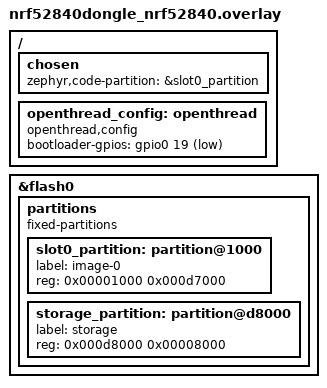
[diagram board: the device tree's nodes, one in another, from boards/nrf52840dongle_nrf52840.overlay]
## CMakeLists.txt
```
#
# Matter temperature sensor on the nRF52840 Dongle.
#
# Based on nrf/samples/matter/temperature_sensor (Nordic-5-Clause).
#

cmake_minimum_required(VERSION 3.20.0)

find_package(Zephyr HINTS $ENV{ZEPHYR_BASE})

project(ansim-sensor-dongle)

# Enable GNU STD support.
include(${ZEPHYR_CONNECTEDHOMEIP_MODULE_DIR}/config/nrfconnect/app/enable-gnu-std.cmake)

# Include all source files that are located in the Matter common directory.
include(${ZEPHYR_NRF_MODULE_DIR}/samples/matter/common/cmake/source_common.cmake)

# Include Data Model utils
include(${ZEPHYR_NRF_MODULE_DIR}/samples/matter/common/cmake/data_model.cmake)

include(${ZEPHYR_NRF_MODULE_DIR}/samples/matter/common/cmake/zap_helpers.cmake)
ncs_get_zap_parent_dir(ZAP_PARENT_DIR)

target_include_directories(app PRIVATE
  src
  ${CMAKE_CURRENT_SOURCE_DIR}/../common
  ${ZAP_PARENT_DIR}
)

target_sources(app PRIVATE
  src/app_task.cpp
  src/main.cpp
  ${CMAKE_CURRENT_SOURCE_DIR}/../common/status_log.cpp
)

ncs_configure_data_model()
```

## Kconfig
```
#
# Matter temperature sensor on the nRF52840 Dongle.
#
# Based on nrf/samples/matter/temperature_sensor (Nordic-5-Clause).
#
mainmenu "Ansim Matter Temperature Sensor"

choice OPENTHREAD_NORDIC_LIBRARY_CONFIGURATION
	default OPENTHREAD_NORDIC_LIBRARY_MTD
endchoice

choice OPENTHREAD_DEVICE_TYPE
	default OPENTHREAD_MTD
endchoice

# The sample's data model (ZAP) declares the ICD Management cluster with the
# check-in commands, so ICD support must stay on. The dongle is USB powered,
# so it runs as a short-idle-time device (no LIT) that polls its parent every
# second: the judge board's reads are answered within one poll period.
config CHIP_ENABLE_ICD_SUPPORT
	default y

config CHIP_ICD_LIT_SUPPORT
	default n

config CHIP_ICD_CHECK_IN_SUPPORT
	default y

config CHIP_ICD_UAT_SUPPORT
	default y

config CHIP_ICD_SLOW_POLL_INTERVAL
	default 1000

config CHIP_ICD_FAST_POLLING_INTERVAL
	default 200

config CHIP_ICD_REPORT_ON_ACTIVE_MODE
	default y

source "$(ZEPHYR_CONNECTEDHOMEIP_MODULE_DIR)/config/nrfconnect/chip-module/Kconfig.features"
source "$(ZEPHYR_CONNECTEDHOMEIP_MODULE_DIR)/config/nrfconnect/chip-module/Kconfig.defaults"
source "$(ZEPHYR_NRF_MODULE_DIR)/samples/matter/common/src/Kconfig"
source "Kconfig.zephyr"
```

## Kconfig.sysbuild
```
#
# The dongle boots through the factory Nordic USB bootloader: no MCUboot,
# no partition manager, no generated factory data partition.
#

choice BOOTLOADER
	default BOOTLOADER_NONE
endchoice

config PARTITION_MANAGER
	default n

config MATTER_FACTORY_DATA_GENERATE
	default n

source "share/sysbuild/Kconfig"
```

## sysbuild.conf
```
SB_CONFIG_MATTER=y
SB_CONFIG_MATTER_OTA=n
SB_CONFIG_MATTER_FACTORY_DATA_GENERATE=n
SB_CONFIG_BOOTLOADER_NONE=y
SB_CONFIG_PARTITION_MANAGER=n
```

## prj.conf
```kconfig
# Matter
CONFIG_CHIP=y
CONFIG_CHIP_PROJECT_CONFIG="src/chip_project_config.h"
CONFIG_CHIP_DEVICE_PRODUCT_NAME="Ansim Temp Sensor"
CONFIG_NCS_SAMPLE_MATTER_ZAP_FILE_PATH="${APPLICATION_CONFIG_DIR}/src/default_zap/temperature_sensor.zap"

# 0x800D: example temperature-sensor-app product ID
CONFIG_CHIP_DEVICE_PRODUCT_ID=32781
CONFIG_STD_CPP17=y

# Test commissioning values. chip-tool: pairing ... 20202021 3840
CONFIG_CHIP_DEVICE_DISCRIMINATOR=0xF00
CONFIG_CHIP_DEVICE_SPAKE2_PASSCODE=20202021

# Advertise for commissioning as soon as the device boots unprovisioned.
CONFIG_CHIP_ENABLE_PAIRING_AUTOSTART=y
CONFIG_CHIP_BLE_EXT_ADVERTISING=y
CONFIG_CHIP_BLE_ADVERTISING_DURATION=60

# No factory data partition on the dongle: device identity comes from the
# CONFIG_CHIP_DEVICE_* test values above.
CONFIG_CHIP_FACTORY_DATA=n
CONFIG_CHIP_FACTORY_DATA_BUILD=n
CONFIG_CHIP_FACTORY_DATA_NONE=y

# No MCUboot on the dongle, so no Matter OTA.
CONFIG_CHIP_OTA_REQUESTOR=n

# The dongle has no NFC antenna; the NFC onboarding payload would pull in
# the NFC tag library and fail to link.
CONFIG_CHIP_NFC_ONBOARDING_PAYLOAD=n

# Chip die temperature sensor
CONFIG_SENSOR=y
CONFIG_TEMP_NRF5=y

# LEDs and button through the DK library (dongle aliases led0..led3, sw0)
CONFIG_DK_LIBRARY=y

# Bluetooth LE
CONFIG_BT_DEVICE_NAME="AnsimTemp"
CONFIG_BT_DEVICE_NAME_MAX=18

# Other settings
CONFIG_THREAD_NAME=y
CONFIG_MPU_STACK_GUARD=y
CONFIG_RESET_ON_FATAL_ERROR=n
CONFIG_CHIP_LIB_SHELL=y
CONFIG_PM_DEVICE=y

# No RTT on the dongle
CONFIG_USE_SEGGER_RTT=n

# Serial log: only this application's lines. The Matter stack, OpenThread
# and the rest of Zephyr stay quiet so the demo log reads as a plain
# status / measurement feed. Set MATTER_LOG_LEVEL_DBG=y to debug the stack.
CONFIG_MATTER_LOG_LEVEL_OFF=y
CONFIG_CHIP_APP_LOG_LEVEL=3
CONFIG_LOG_DEFAULT_LEVEL=1
```

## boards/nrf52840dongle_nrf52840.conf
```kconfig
# Link the application into the flash region defined by the overlay
# (0x1000-0xD8000), below the dongle's Nordic USB bootloader.
CONFIG_USE_DT_CODE_PARTITION=y

# Settings on storage_partition (NVS); no partition manager on the dongle.
CONFIG_SETTINGS=y
CONFIG_SETTINGS_NVS=y
CONFIG_NVS=y
CONFIG_FLASH=y
CONFIG_FLASH_MAP=y

# Console, log and shell over USB CDC ACM (the dongle has no UART-to-USB).
CONFIG_USB_DEVICE_STACK_NEXT=y
CONFIG_CDC_ACM_SERIAL_INITIALIZE_AT_BOOT=y
CONFIG_CDC_ACM_SERIAL_MANUFACTURER_STRING="Nordic Semiconductor ASA"
CONFIG_CDC_ACM_SERIAL_PRODUCT_STRING="Ansim Matter Temp Sensor"
CONFIG_CDC_ACM_SERIAL_VID=0x1915
CONFIG_CDC_ACM_SERIAL_PID=0x0000
CONFIG_UART_LINE_CTRL=y

# "gpio conf gpio@50000000 19 o0" pulls reset low and enters the USB bootloader,
# so the dongle can be re-flashed without reaching the reset button.
CONFIG_GPIO=y
CONFIG_GPIO_SHELL=y
CONFIG_OPENTHREAD_PLATFORM_BOOTLOADER_MODE_GPIO=y
```

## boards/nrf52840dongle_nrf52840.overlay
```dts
/*
 * nRF52840 Dongle flash layout for a Matter application that runs directly
 * under the Nordic USB bootloader (no MCUboot).
 *
 *   0x00000 - 0x01000  MBR (factory programmed)
 *   0x01000 - 0xD8000  application            (slot0_partition, 860 KB)
 *   0xD8000 - 0xE0000  settings / NVS         (storage_partition, 32 KB)
 *   0xE0000 - 0xFE000  Nordic USB bootloader
 *   0xFE000 - 0x100000 MBR params + bootloader settings
 */

/delete-node/ &boot_partition;
/delete-node/ &slot0_partition;
/delete-node/ &slot1_partition;
/delete-node/ &storage_partition;

&flash0 {
	partitions {
		compatible = "fixed-partitions";
		#address-cells = <1>;
		#size-cells = <1>;

		slot0_partition: partition@1000 {
			label = "image-0";
			reg = <0x00001000 0x000d7000>;
		};

		storage_partition: partition@d8000 {
			label = "storage";
			reg = <0x000d8000 0x00008000>;
		};
	};
};

/ {
	chosen {
		zephyr,code-partition = &slot0_partition;
	};

	/*
	 * P0.19 is wired to the reset line. Driving it low reboots the dongle
	 * into the USB bootloader. The OpenThread platform exposes this through
	 * CONFIG_OPENTHREAD_PLATFORM_BOOTLOADER_MODE_GPIO.
	 */
	openthread_config: openthread {
		compatible = "openthread,config";
		bootloader-gpios = <&gpio0 19 GPIO_ACTIVE_LOW>;
	};
};
```

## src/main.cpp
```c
/*
 * Matter temperature sensor on the nRF52840 Dongle.
 *
 * Based on nrf/samples/matter/temperature_sensor (Nordic-5-Clause).
 */

#include "app_task.h"

#include <zephyr/logging/log.h>

LOG_MODULE_REGISTER(app, CONFIG_CHIP_APP_LOG_LEVEL);

int main()
{
	CHIP_ERROR err = AppTask::Instance().StartApp();

	LOG_ERR("Exited with code %" CHIP_ERROR_FORMAT, err.Format());
	return err == CHIP_NO_ERROR ? EXIT_SUCCESS : EXIT_FAILURE;
}
```

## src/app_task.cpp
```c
/*
 * Matter temperature sensor on the nRF52840 Dongle.
 *
 * Based on nrf/samples/matter/temperature_sensor (Nordic-5-Clause).
 * The simulated temperature ramp of the sample is replaced by the
 * temperature sensor inside the nRF52840 chip.
 */

#include "app_task.h"
#include "status_log.h"

#include "app/matter_init.h"
#include "app/task_executor.h"
#include "board/board.h"
#include "clusters/identify.h"
#include "lib/core/CHIPError.h"

#include <app-common/zap-generated/attributes/Accessors.h>

#include <zephyr/device.h>
#include <zephyr/drivers/sensor.h>
#include <zephyr/logging/log.h>

#include <cstdlib>

LOG_MODULE_DECLARE(app, CONFIG_CHIP_APP_LOG_LEVEL);

using namespace ::chip;
using namespace ::chip::app;
using namespace ::chip::DeviceLayer;

namespace
{
constexpr chip::EndpointId kTemperatureSensorEndpointId = 1;

Nrf::Matter::IdentifyCluster sIdentifyCluster(kTemperatureSensorEndpointId);

const device *const sTempDev = DEVICE_DT_GET(DT_NODELABEL(temp));
} /* namespace */

/* The dongle has one button (sw0 = DK button 1). The board module's default
 * handler owns it for factory reset (long press); a short press is the ICD
 * user-action trigger that puts the device in active mode for a while. */
void AppTask::ButtonEventHandler(Nrf::ButtonState state, Nrf::ButtonMask hasChanged)
{
#ifdef CONFIG_CHIP_ICD_UAT_SUPPORT
	if (DK_BTN1_MSK & state & hasChanged) {
		LOG_INF("ICD UserActiveMode has been triggered.");
		Server::GetInstance().GetICDManager().OnNetworkActivity();
	}
#else
	ARG_UNUSED(state);
	ARG_UNUSED(hasChanged);
#endif
}

void AppTask::UpdateTemperatureMeasurement()
{
	sensor_value temperature;
	int result = sensor_sample_fetch(sTempDev);

	if (result != 0) {
		LOG_ERR("Fetching the die temperature failed with: %d", result);
		return;
	}

	result = sensor_channel_get(sTempDev, SENSOR_CHAN_DIE_TEMP, &temperature);
	if (result != 0) {
		LOG_ERR("Reading the die temperature failed with: %d", result);
		return;
	}

	/* val1 is the integer part, val2 the fraction in millionths.
	 * Cluster unit is 0.01 degC, so val2 / 10000. */
	int32_t centi = temperature.val1 * 100 + temperature.val2 / 10000;

	if (centi < mTemperatureSensorMinValue || centi > mTemperatureSensorMaxValue) {
		LOG_WRN("temp %d.%02d C outside the cluster range %d..%d", centi / 100, abs(centi % 100),
			mTemperatureSensorMinValue, mTemperatureSensorMaxValue);
		centi = centi < mTemperatureSensorMinValue ? mTemperatureSensorMinValue : mTemperatureSensorMaxValue;
	}

	mCurrentTemperature = static_cast<int16_t>(centi);
	LOG_INF("temp %d.%02d C", mCurrentTemperature / 100, abs(mCurrentTemperature % 100));
}

void AppTask::UpdateTemperatureTimeoutCallback(k_timer *timer)
{
	if (!timer || !timer->user_data) {
		return;
	}

	DeviceLayer::PlatformMgr().ScheduleWork(
		[](intptr_t p) {
			AppTask::Instance().UpdateTemperatureMeasurement();

			Protocols::InteractionModel::Status status =
				Clusters::TemperatureMeasurement::Attributes::MeasuredValue::Set(
					kTemperatureSensorEndpointId, AppTask::Instance().GetCurrentTemperature());

			if (status != Protocols::InteractionModel::Status::Success) {
				LOG_ERR("Updating temperature measurement failed %x", to_underlying(status));
			}
		},
		reinterpret_cast<intptr_t>(timer->user_data));
}

CHIP_ERROR AppTask::Init()
{
	/* Initialize Matter stack */
	ReturnErrorOnFailure(Nrf::Matter::PrepareServer());

	if (!Nrf::GetBoard().Init(ButtonEventHandler)) {
		LOG_ERR("User interface initialization failed.");
		return CHIP_ERROR_INCORRECT_STATE;
	}

	/* Register Matter event handler that controls the connectivity status LED based on the captured Matter network
	 * state. */
	ReturnErrorOnFailure(Nrf::Matter::RegisterEventHandler(Nrf::Board::DefaultMatterEventHandler, 0));
	ReturnErrorOnFailure(StatusLog::Init());

	if (!device_is_ready(sTempDev)) {
		LOG_ERR("Die temperature sensor not ready");
		return chip::System::MapErrorZephyr(-ENODEV);
	}

	ReturnErrorOnFailure(sIdentifyCluster.Init());

	ReturnErrorOnFailure(Nrf::Matter::StartServer());
	StatusLog::PrintCurrent();
	return CHIP_NO_ERROR;
}

CHIP_ERROR AppTask::StartApp()
{
	ReturnErrorOnFailure(Init());

	DataModel::Nullable<int16_t> val;
	Protocols::InteractionModel::Status status =
		Clusters::TemperatureMeasurement::Attributes::MinMeasuredValue::Get(kTemperatureSensorEndpointId, val);

	if (status != Protocols::InteractionModel::Status::Success || val.IsNull()) {
		LOG_ERR("Failed to get temperature measurement min value %x", to_underlying(status));
		return CHIP_ERROR_INCORRECT_STATE;
	}

	mTemperatureSensorMinValue = val.Value();

	status = Clusters::TemperatureMeasurement::Attributes::MaxMeasuredValue::Get(kTemperatureSensorEndpointId, val);

	if (status != Protocols::InteractionModel::Status::Success || val.IsNull()) {
		LOG_ERR("Failed to get temperature measurement max value %x", to_underlying(status));
		return CHIP_ERROR_INCORRECT_STATE;
	}

	mTemperatureSensorMaxValue = val.Value();

	k_timer_init(&mTimer, AppTask::UpdateTemperatureTimeoutCallback, nullptr);
	k_timer_user_data_set(&mTimer, this);
	k_timer_start(&mTimer, K_MSEC(kTemperatureMeasurementIntervalMs), K_MSEC(kTemperatureMeasurementIntervalMs));

	while (true) {
		Nrf::DispatchNextTask();
	}

	return CHIP_NO_ERROR;
}
```

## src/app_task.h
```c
/*
 * Matter temperature sensor on the nRF52840 Dongle.
 *
 * Based on nrf/samples/matter/temperature_sensor (Nordic-5-Clause).
 */

#pragma once

#include "board/board.h"

#include <platform/CHIPDeviceLayer.h>

class AppTask {
public:
	static AppTask &Instance()
	{
		static AppTask sAppTask;
		return sAppTask;
	};

	CHIP_ERROR StartApp();

	/* Reads the chip die temperature into mCurrentTemperature.
	 * Unit is the cluster's: 100 x degrees Celsius (0.01 degC resolution). */
	void UpdateTemperatureMeasurement();

	int16_t GetCurrentTemperature() const { return mCurrentTemperature; }

private:
	CHIP_ERROR Init();
	k_timer mTimer;

	static constexpr uint16_t kTemperatureMeasurementIntervalMs = 1000;

	static void UpdateTemperatureTimeoutCallback(k_timer *timer);

	static void ButtonEventHandler(Nrf::ButtonState state, Nrf::ButtonMask hasChanged);

	int16_t mTemperatureSensorMaxValue = 0;
	int16_t mTemperatureSensorMinValue = 0;
	int16_t mCurrentTemperature = 0;
};
```

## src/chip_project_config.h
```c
/*
 * Project-specific overrides of the default Matter (CHIP) configuration.
 * None needed for the temperature sensor.
 */

#pragma once
```
